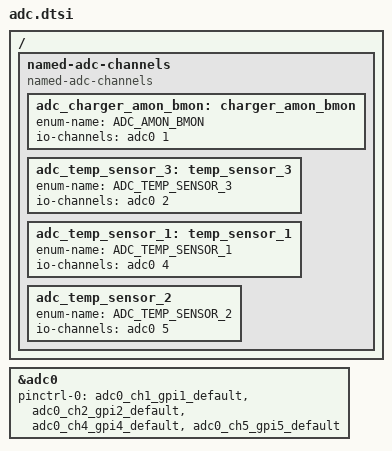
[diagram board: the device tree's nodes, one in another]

/* Copyright 2025 The ChromiumOS Authors
 * Use of this source code is governed by a BSD-style license that can be
 * found in the LICENSE file.
 */
/{
        named-adc-channels {
		compatible = "named-adc-channels";
		adc_charger_amon_bmon: charger_amon_bmon {
			enum-name = "ADC_AMON_BMON";
			io-channels = <&adc0 1>;
		};
		adc_temp_sensor_3: temp_sensor_3 {
			enum-name = "ADC_TEMP_SENSOR_3";
			io-channels = <&adc0 2>;
		};
		adc_temp_sensor_1: temp_sensor_1 {
			enum-name = "ADC_TEMP_SENSOR_1";
			io-channels = <&adc0 4>;
		};
		adc_temp_sensor_2: adc_temp_sensor_2 {
			enum-name = "ADC_TEMP_SENSOR_2";
			io-channels = <&adc0 5>;
		};
	};
};
&adc0 {
	status = "okay";
	pinctrl-0 = <&adc0_ch1_gpi1_default
		&adc0_ch2_gpi2_default
		&adc0_ch4_gpi4_default
		&adc0_ch5_gpi5_default>;
	pinctrl-names = "default";
};
